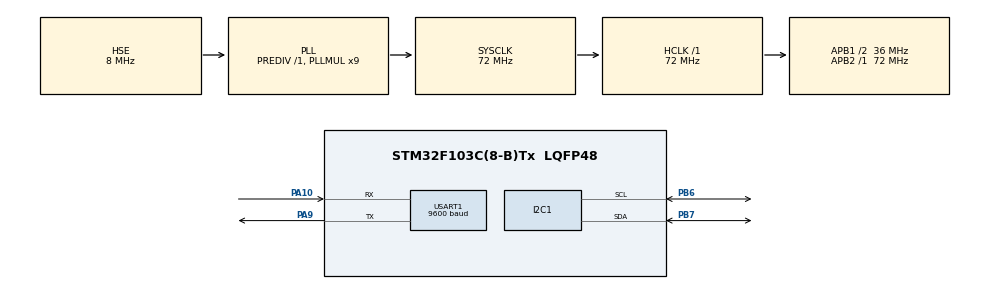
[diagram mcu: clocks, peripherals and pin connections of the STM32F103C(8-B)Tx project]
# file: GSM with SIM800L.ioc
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Dma.Request0=USART1_RX
Dma.USART1_RX.0.Direction=DMA_PERIPH_TO_MEMORY
Dma.USART1_RX.0.Instance=DMA1_Channel5
Dma.USART1_RX.0.MemDataAlignment=DMA_MDATAALIGN_BYTE
Dma.USART1_RX.0.MemInc=DMA_MINC_ENABLE
Dma.USART1_RX.0.Mode=DMA_CIRCULAR
Dma.USART1_RX.0.PeriphDataAlignment=DMA_PDATAALIGN_BYTE
Dma.USART1_RX.0.PeriphInc=DMA_PINC_DISABLE
Dma.USART1_RX.0.Priority=DMA_PRIORITY_LOW
Mcu.Family=STM32F1
Mcu.Name=STM32F103C(8-B)Tx
Mcu.Package=LQFP48
NVIC.DMA1_Channel5_IRQn=true\:0\:0\:false\:false\:true\:false\:true\:true
NVIC.PriorityGroup=NVIC_PRIORITYGROUP_4
PA10.Mode=Asynchronous
PA10.Signal=USART1_RX
PA13.Mode=Serial_Wire
PA13.Signal=SYS_JTMS-SWDIO
PA14.Mode=Serial_Wire
PA14.Signal=SYS_JTCK-SWCLK
PA9.Mode=Asynchronous
PA9.Signal=USART1_TX
PB6.Mode=I2C
PB6.Signal=I2C1_SCL
PB7.Mode=I2C
PB7.Signal=I2C1_SDA
PD0-OSC_IN.Mode=HSE-External-Oscillator
PD0-OSC_IN.Signal=RCC_OSC_IN
PD1-OSC_OUT.Mode=HSE-External-Oscillator
PD1-OSC_OUT.Signal=RCC_OSC_OUT
ProjectManager.HeapSize=0x200
ProjectManager.StackSize=0x400
ProjectManager.TargetToolchain=STM32CubeIDE
RCC.AHBFreq_Value=72000000
RCC.APB1CLKDivider=RCC_HCLK_DIV2
RCC.APB1Freq_Value=36000000
RCC.APB1TimFreq_Value=72000000
RCC.APB2Freq_Value=72000000
RCC.APB2TimFreq_Value=72000000
RCC.HCLKFreq_Value=72000000
RCC.PLLMUL=RCC_PLL_MUL9
RCC.PLLSourceVirtual=RCC_PLLSOURCE_HSE
RCC.SYSCLKFreq_VALUE=72000000
RCC.SYSCLKSource=RCC_SYSCLKSOURCE_PLLCLK
RCC.USBFreq_Value=72000000
USART1.BaudRate=9600
USART1.VirtualMode=VM_ASYNC
board=custom

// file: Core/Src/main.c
/* USER CODE BEGIN Header */
/**
  ******************************************************************************
  * @file           : main.c
  * @brief          : Main program body
  ******************************************************************************
  * @attention
  *
  * Copyright (c) 2025 STMicroelectronics.
  * All rights reserved.
  *
  * This software is licensed under terms that can be found in the LICENSE file
  * in the root directory of this software component.
  * If no LICENSE file comes with this software, it is provided AS-IS.
  *
  ******************************************************************************
  */
/* USER CODE END Header */
#include "main.h"
#include "general.h"

I2C_HandleTypeDef hi2c1;

UART_HandleTypeDef huart1;
DMA_HandleTypeDef hdma_usart1_rx;

void SystemClock_Config(void);
static void MX_I2C1_Init(void);
static void MX_USART1_UART_Init(void);
static void MX_DMA_Init(void);
static void MX_GPIO_Init(void);

int main(void)
{

  /* MCU Configuration--------------------------------------------------------*/

  /* Reset of all peripherals, Initializes the Flash interface and the Systick. */
  HAL_Init();

  /* Configure the system clock */
  SystemClock_Config();

  /* Initialize all configured peripherals */
  MX_I2C1_Init();
  MX_USART1_UART_Init();
  MX_DMA_Init();
  MX_GPIO_Init();

  /* Infinite loop */
  General_Run();
  while (1)
  {
	  //General_Run();
  }
}

void SystemClock_Config(void)
{
  RCC_OscInitTypeDef RCC_OscInitStruct = {0};
  RCC_ClkInitTypeDef RCC_ClkInitStruct = {0};

  /** Initializes the RCC Oscillators according to the specified parameters
  * in the RCC_OscInitTypeDef structure.
  */
  RCC_OscInitStruct.OscillatorType = RCC_OSCILLATORTYPE_HSE;
  RCC_OscInitStruct.HSEState = RCC_HSE_ON;
  RCC_OscInitStruct.HSEPredivValue = RCC_HSE_PREDIV_DIV1;
  RCC_OscInitStruct.HSIState = RCC_HSI_ON;
  RCC_OscInitStruct.PLL.PLLState = RCC_PLL_ON;
  RCC_OscInitStruct.PLL.PLLSource = RCC_PLLSOURCE_HSE;
  RCC_OscInitStruct.PLL.PLLMUL = RCC_PLL_MUL9;
  if (HAL_RCC_OscConfig(&RCC_OscInitStruct) != HAL_OK)
  {
    Error_Handler();
  }

  /** Initializes the CPU, AHB and APB buses clocks
  */
  RCC_ClkInitStruct.ClockType = RCC_CLOCKTYPE_HCLK|RCC_CLOCKTYPE_SYSCLK
                              |RCC_CLOCKTYPE_PCLK1|RCC_CLOCKTYPE_PCLK2;
  RCC_ClkInitStruct.SYSCLKSource = RCC_SYSCLKSOURCE_PLLCLK;
  RCC_ClkInitStruct.AHBCLKDivider = RCC_SYSCLK_DIV1;
  RCC_ClkInitStruct.APB1CLKDivider = RCC_HCLK_DIV2;
  RCC_ClkInitStruct.APB2CLKDivider = RCC_HCLK_DIV1;

  if (HAL_RCC_ClockConfig(&RCC_ClkInitStruct, FLASH_LATENCY_2) != HAL_OK)
  {
    Error_Handler();
  }
}

static void MX_I2C1_Init(void)
{
  hi2c1.Instance = I2C1;
  hi2c1.Init.ClockSpeed = 400000;
  hi2c1.Init.DutyCycle = I2C_DUTYCYCLE_2;
  hi2c1.Init.OwnAddress1 = 0;
  hi2c1.Init.AddressingMode = I2C_ADDRESSINGMODE_7BIT;
  hi2c1.Init.DualAddressMode = I2C_DUALADDRESS_DISABLE;
  hi2c1.Init.OwnAddress2 = 0;
  hi2c1.Init.GeneralCallMode = I2C_GENERALCALL_DISABLE;
  hi2c1.Init.NoStretchMode = I2C_NOSTRETCH_DISABLE;
  if (HAL_I2C_Init(&hi2c1) != HAL_OK)
  {
    Error_Handler();
  }
}

static void MX_USART1_UART_Init(void)
{

  huart1.Instance = USART1;
  huart1.Init.BaudRate = 9600;
  huart1.Init.WordLength = UART_WORDLENGTH_8B;
  huart1.Init.StopBits = UART_STOPBITS_1;
  huart1.Init.Parity = UART_PARITY_NONE;
  huart1.Init.Mode = UART_MODE_TX_RX;
  huart1.Init.HwFlowCtl = UART_HWCONTROL_NONE;
  huart1.Init.OverSampling = UART_OVERSAMPLING_16;
  if (HAL_UART_Init(&huart1) != HAL_OK)
  {
    Error_Handler();
  }

}

static void MX_DMA_Init(void)
{

  /* DMA controller clock enable */
  __HAL_RCC_DMA1_CLK_ENABLE();

  /* DMA interrupt init */
  /* DMA1_Channel5_IRQn interrupt configuration */
  HAL_NVIC_SetPriority(DMA1_Channel5_IRQn, 0, 0);
  HAL_NVIC_EnableIRQ(DMA1_Channel5_IRQn);

}

static void MX_GPIO_Init(void)
{
  /* USER CODE BEGIN MX_GPIO_Init_1 */
	GPIO_InitTypeDef GPIO_InitStruct = {0};
  /* USER CODE END MX_GPIO_Init_1 */

  /* GPIO Ports Clock Enable */
  __HAL_RCC_GPIOD_CLK_ENABLE();
  __HAL_RCC_GPIOA_CLK_ENABLE();
  __HAL_RCC_GPIOB_CLK_ENABLE();

  /* USER CODE BEGIN MX_GPIO_Init_2 */
  GPIO_InitStruct.Pin = GPIO_PIN_13 | GPIO_PIN_14 | GPIO_PIN_15;
  GPIO_InitStruct.Mode = GPIO_MODE_INPUT;
  GPIO_InitStruct.Pull = GPIO_PULLUP;
  HAL_GPIO_Init(GPIOB, &GPIO_InitStruct);

  GPIO_InitStruct.Pin = GPIO_PIN_12;
  GPIO_InitStruct.Mode = GPIO_MODE_OUTPUT_PP;
  GPIO_InitStruct.Pull = GPIO_PULLDOWN;
  GPIO_InitStruct.Speed = GPIO_SPEED_FREQ_LOW;
  HAL_GPIO_Init(GPIOB, &GPIO_InitStruct);

  /* USER CODE END MX_GPIO_Init_2 */
}

void Error_Handler(void)
{
  __disable_irq();
  while (1)
  {
  }
}
